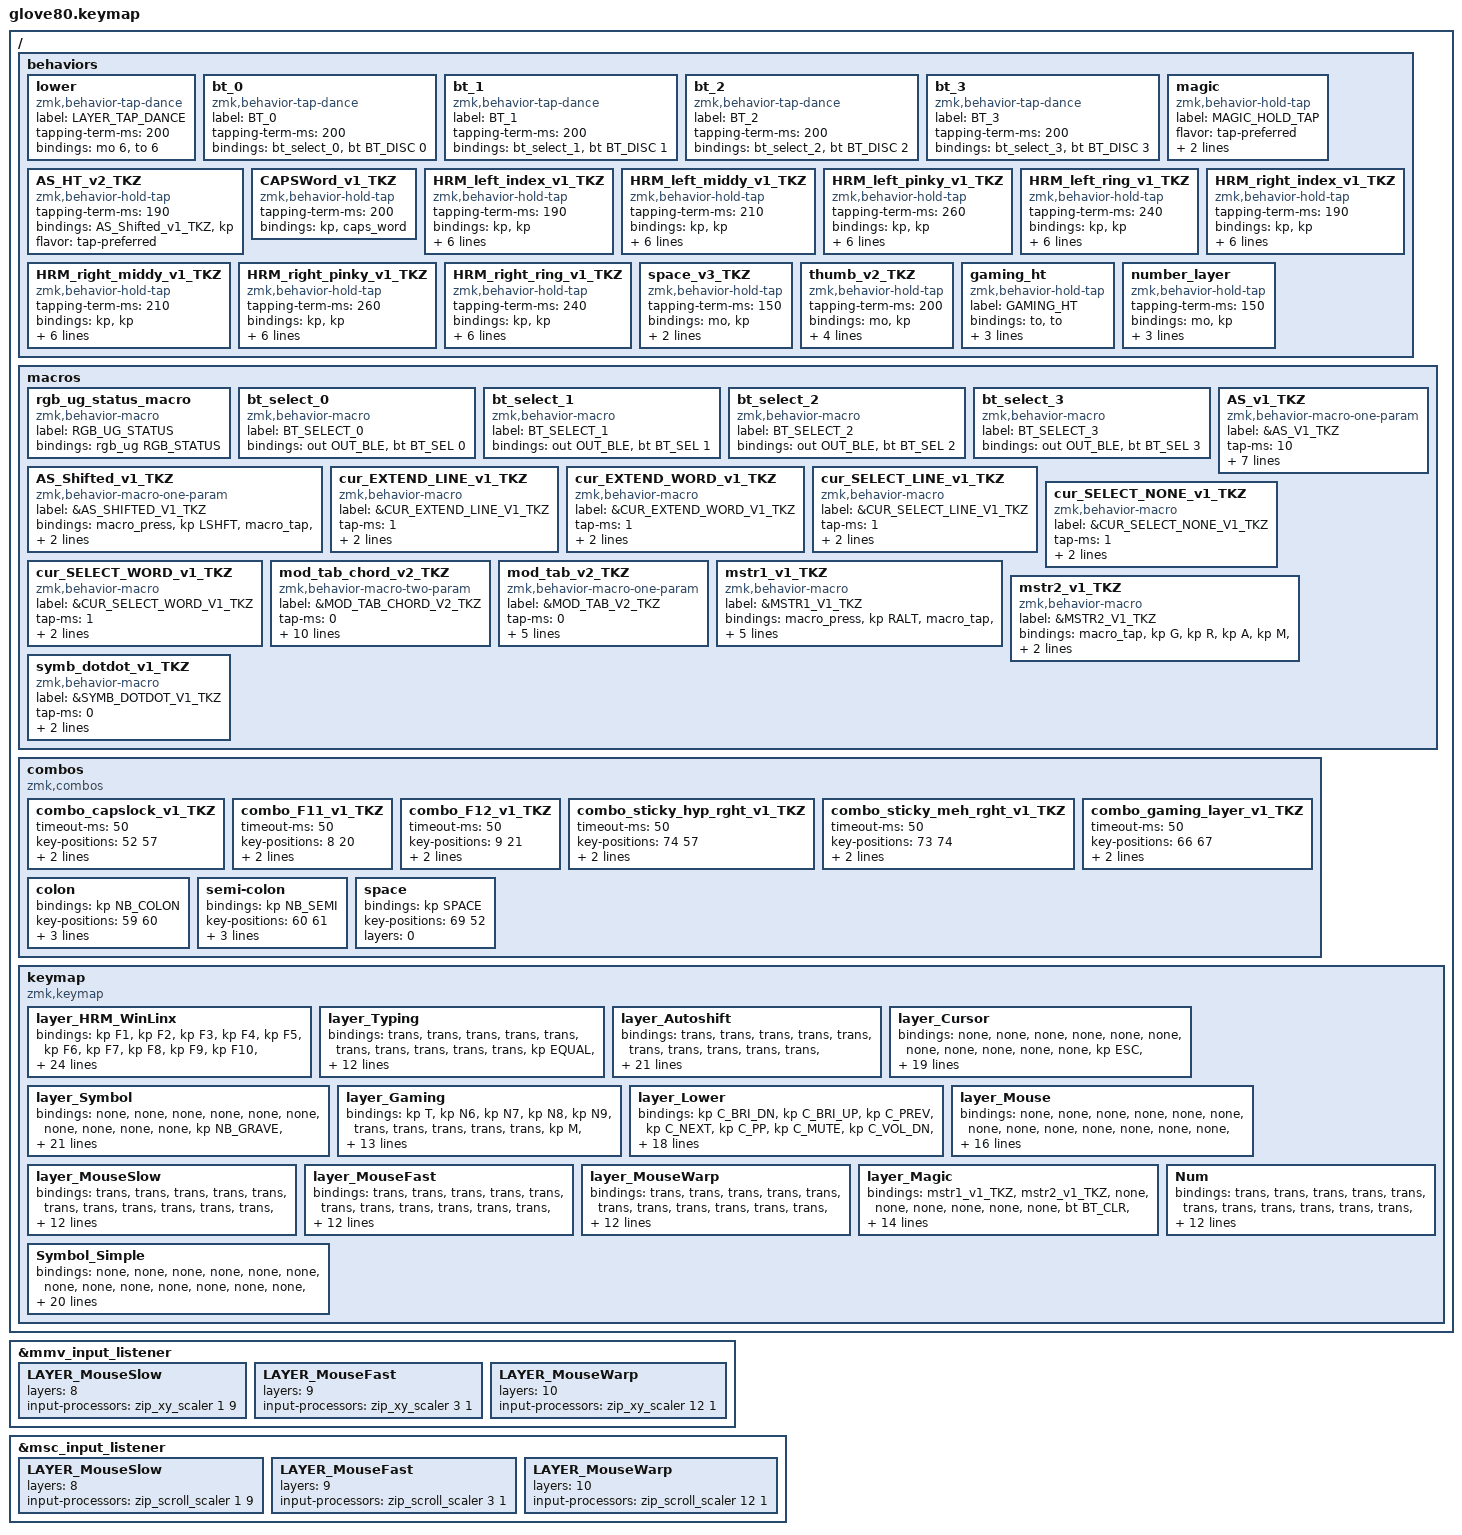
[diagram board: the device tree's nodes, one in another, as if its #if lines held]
/*
 * Copyright (c) 2020 The ZMK Contributors
 * Copyright (c) 2025 Innaworks Development Limited, trading as MoErgo
 *
 * SPDX-License-Identifier: MIT
 */
/* THIS FILE WAS GENERATED BY GLOVE80 LAYOUT EDITOR
 *
 * This file was generated automatically. You may or may not want to
 * edit it directly.
 */
/* Include all behavior includes needed */
/* On demand includes */

#include "keys_nb.h"
#include <dt-bindings/zmk/input_transform.h>
#include <input/processors.dtsi>
#include <behaviors.dtsi>
#include <dt-bindings/zmk/bt.h>
#include <dt-bindings/zmk/keys.h>
#include <dt-bindings/zmk/outputs.h>
#include <dt-bindings/zmk/pointing.h>
#include <dt-bindings/zmk/rgb.h>

/* Automatically generated layer name #define */

#define LAYER_HRM_WinLinx 0
#define LAYER_Typing 1
#define LAYER_Autoshift 2
#define LAYER_Cursor 3
#define LAYER_Symbol 4
#define LAYER_Gaming 5
#define LAYER_Lower 6
#define LAYER_Mouse 7
#define LAYER_MouseSlow 8
#define LAYER_MouseFast 9
#define LAYER_MouseWarp 10
#define LAYER_Magic 11
#define LAYER_Symbol_2 12

/* To deal with the situation where there is no Lower layer, to keep &lower happy */

#ifndef LAYER_Lower

#define LAYER_Lower 0

#endif

/* Custom Device-tree */
/* Input Listeners */

&mmv_input_listener {
    // LAYER_MouseSlow

    LAYER_MouseSlow {
        layers = <8>;
        input-processors = <&zip_xy_scaler 1 9>;
    };

    // LAYER_MouseFast

    LAYER_MouseFast {
        layers = <9>;
        input-processors = <&zip_xy_scaler 3 1>;
    };

    // LAYER_MouseFast

    LAYER_MouseWarp {
        layers = <10>;
        input-processors = <&zip_xy_scaler 12 1>;
    };
};

&msc_input_listener {
    // LAYER_MouseSlow

    LAYER_MouseSlow {
        layers = <8>;
        input-processors = <&zip_scroll_scaler 1 9>;
    };

    // LAYER_MouseFast

    LAYER_MouseFast {
        layers = <9>;
        input-processors = <&zip_scroll_scaler 3 1>;
    };

    // LAYER_MouseWarp

    LAYER_MouseWarp {
        layers = <10>;
        input-processors = <&zip_scroll_scaler 12 1>;
    };
};

/* System behavior and Macros */

/ {
    behaviors {
        // For the "layer" key, it'd nice to be able to use it as either a shift or a toggle.
        // Configure it as a tap dance, so the first tap (or hold) is a &mo and the second tap is a &to

        lower: lower {
            compatible = "zmk,behavior-tap-dance";
            label = "LAYER_TAP_DANCE";
            #binding-cells = <0>;
            tapping-term-ms = <200>;
            bindings = <&mo 6>, <&to 6>;
        };
    };
};

/ {
    macros {
        rgb_ug_status_macro: rgb_ug_status_macro {
            label = "RGB_UG_STATUS";
            compatible = "zmk,behavior-macro";
            #binding-cells = <0>;
            bindings = <&rgb_ug RGB_STATUS>;
        };
    };
};

/ {
    #ifdef BT_DISC_CMD

    behaviors {
        bt_0: bt_0 {
            compatible = "zmk,behavior-tap-dance";
            label = "BT_0";
            #binding-cells = <0>;
            tapping-term-ms = <200>;
            bindings = <&bt_select_0>, <&bt BT_DISC 0>;
        };

        bt_1: bt_1 {
            compatible = "zmk,behavior-tap-dance";
            label = "BT_1";
            #binding-cells = <0>;
            tapping-term-ms = <200>;
            bindings = <&bt_select_1>, <&bt BT_DISC 1>;
        };

        bt_2: bt_2 {
            compatible = "zmk,behavior-tap-dance";
            label = "BT_2";
            #binding-cells = <0>;
            tapping-term-ms = <200>;
            bindings = <&bt_select_2>, <&bt BT_DISC 2>;
        };

        bt_3: bt_3 {
            compatible = "zmk,behavior-tap-dance";
            label = "BT_3";
            #binding-cells = <0>;
            tapping-term-ms = <200>;
            bindings = <&bt_select_3>, <&bt BT_DISC 3>;
        };
    };

    macros {
        bt_select_0: bt_select_0 {
            label = "BT_SELECT_0";
            compatible = "zmk,behavior-macro";
            #binding-cells = <0>;
            bindings = <&out OUT_BLE &bt BT_SEL 0>;
        };

        bt_select_1: bt_select_1 {
            label = "BT_SELECT_1";
            compatible = "zmk,behavior-macro";
            #binding-cells = <0>;
            bindings = <&out OUT_BLE &bt BT_SEL 1>;
        };

        bt_select_2: bt_select_2 {
            label = "BT_SELECT_2";
            compatible = "zmk,behavior-macro";
            #binding-cells = <0>;
            bindings = <&out OUT_BLE &bt BT_SEL 2>;
        };

        bt_select_3: bt_select_3 {
            label = "BT_SELECT_3";
            compatible = "zmk,behavior-macro";
            #binding-cells = <0>;
            bindings = <&out OUT_BLE &bt BT_SEL 3>;
        };
    };

    #else

    macros {
        bt_0: bt_0 {
            label = "BT_0";
            compatible = "zmk,behavior-macro";
            #binding-cells = <0>;
            bindings = <&out OUT_BLE &bt BT_SEL 0>;
        };

        bt_1: bt_1 {
            label = "BT_1";
            compatible = "zmk,behavior-macro";
            #binding-cells = <0>;
            bindings = <&out OUT_BLE &bt BT_SEL 1>;
        };

        bt_2: bt_2 {
            label = "BT_2";
            compatible = "zmk,behavior-macro";
            #binding-cells = <0>;
            bindings = <&out OUT_BLE &bt BT_SEL 2>;
        };

        bt_3: bt_3 {
            label = "BT_3";
            compatible = "zmk,behavior-macro";
            #binding-cells = <0>;
            bindings = <&out OUT_BLE &bt BT_SEL 3>;
        };
    };

    #endif
};

/ {
    behaviors {
        magic: magic {
            compatible = "zmk,behavior-hold-tap";
            label = "MAGIC_HOLD_TAP";
            #binding-cells = <2>;
            flavor = "tap-preferred";
            tapping-term-ms = <200>;
            bindings = <&mo>, <&rgb_ug_status_macro>;
        };
    };
};

/* #define for key positions */

#define POS_LH_T1 52
#define POS_LH_T2 53
#define POS_LH_T3 54
#define POS_LH_T4 69
#define POS_LH_T5 70
#define POS_LH_T6 71
#define POS_LH_C1R2 15
#define POS_LH_C1R3 27
#define POS_LH_C1R4 39
#define POS_LH_C1R5 51
#define POS_LH_C2R1 4
#define POS_LH_C2R2 14
#define POS_LH_C2R3 26
#define POS_LH_C2R4 38
#define POS_LH_C2R5 50
#define POS_LH_C2R6 68
#define POS_LH_C3R1 3
#define POS_LH_C3R2 13
#define POS_LH_C3R3 25
#define POS_LH_C3R4 37
#define POS_LH_C3R5 49
#define POS_LH_C3R6 67
#define POS_LH_C4R1 2
#define POS_LH_C4R2 12
#define POS_LH_C4R3 24
#define POS_LH_C4R4 36
#define POS_LH_C4R5 48
#define POS_LH_C4R6 66
#define POS_LH_C5R1 1
#define POS_LH_C5R2 11
#define POS_LH_C5R3 23
#define POS_LH_C5R4 35
#define POS_LH_C5R5 47
#define POS_LH_C5R6 65
#define POS_LH_C6R1 0
#define POS_LH_C6R2 10
#define POS_LH_C6R3 22
#define POS_LH_C6R4 34
#define POS_LH_C6R5 46
#define POS_LH_C6R6 64
#define POS_RH_T1 57
#define POS_RH_T2 56
#define POS_RH_T3 55
#define POS_RH_T4 74
#define POS_RH_T5 73
#define POS_RH_T6 72
#define POS_RH_C1R2 16
#define POS_RH_C1R3 28
#define POS_RH_C1R4 40
#define POS_RH_C1R5 58
#define POS_RH_C2R1 5
#define POS_RH_C2R2 17
#define POS_RH_C2R3 29
#define POS_RH_C2R4 41
#define POS_RH_C2R5 59
#define POS_RH_C2R6 75
#define POS_RH_C3R1 6
#define POS_RH_C3R2 18
#define POS_RH_C3R3 30
#define POS_RH_C3R4 42
#define POS_RH_C3R5 60
#define POS_RH_C3R6 76
#define POS_RH_C4R1 7
#define POS_RH_C4R2 19
#define POS_RH_C4R3 31
#define POS_RH_C4R4 43
#define POS_RH_C4R5 61
#define POS_RH_C4R6 77
#define POS_RH_C5R1 8
#define POS_RH_C5R2 20
#define POS_RH_C5R3 32
#define POS_RH_C5R4 44
#define POS_RH_C5R5 62
#define POS_RH_C5R6 78
#define POS_RH_C6R1 9
#define POS_RH_C6R2 21
#define POS_RH_C6R3 33
#define POS_RH_C6R4 45
#define POS_RH_C6R5 63
#define POS_RH_C6R6 79

/* Custom Defined Behaviors */

/ {
};

/* Automatically generated macro definitions */

/ {
    macros {
        // AutoShift Helper- &AS main macro is chained to &AS_HT hold tap and &AS_Shifted macro - TailorKey

        AS_Shifted_v1_TKZ: AS_Shifted_v1_TKZ {
            label = "&AS_SHIFTED_V1_TKZ";
            compatible = "zmk,behavior-macro-one-param";
            #binding-cells = <1>;
            bindings =
                <&macro_press>,
                <&kp LSHFT>,
                <&macro_tap>,
                <&macro_param_1to1 &kp MACRO_PLACEHOLDER>,
                <&macro_release>,
                <&kp LSHFT>;
        };

        // AutoShift (Assign &AS to a Key) - &AS main macro is chained to &AS_HT hold tap and &AS_Shifted macro - TailorKey

        AS_v1_TKZ: AS_v1_TKZ {
            label = "&AS_V1_TKZ";
            compatible = "zmk,behavior-macro-one-param";
            #binding-cells = <1>;
            tap-ms = <10>;
            wait-ms = <10>;
            bindings =
                <&macro_press>,
                <&macro_param_1to1 &macro_param_1to2 &AS_HT_v2_TKZ MACRO_PLACEHOLDER MACRO_PLACEHOLDER>,
                <&macro_pause_for_release>,
                <&macro_release>,
                <&macro_param_1to1 &macro_param_1to2 &AS_HT_v2_TKZ MACRO_PLACEHOLDER MACRO_PLACEHOLDER>;
        };

        // Cursor Layer - Extent Line (seq) - TailorKey

        cur_EXTEND_LINE_v1_TKZ: cur_EXTEND_LINE_v1_TKZ {
            label = "&CUR_EXTEND_LINE_V1_TKZ";
            compatible = "zmk,behavior-macro";
            #binding-cells = <0>;
            tap-ms = <1>;
            wait-ms = <1>;
            bindings = <&kp LS(END)>;
        };

        // Cursor Layer - Extend Word (seq) - TailorKey

        cur_EXTEND_WORD_v1_TKZ: cur_EXTEND_WORD_v1_TKZ {
            label = "&CUR_EXTEND_WORD_V1_TKZ";
            compatible = "zmk,behavior-macro";
            #binding-cells = <0>;
            tap-ms = <1>;
            wait-ms = <1>;
            bindings = <&kp LC(LS(RIGHT))>;
        };

        // Cursor Layer - Select Line (seq) - TailorKey

        cur_SELECT_LINE_v1_TKZ: cur_SELECT_LINE_v1_TKZ {
            label = "&CUR_SELECT_LINE_V1_TKZ";
            compatible = "zmk,behavior-macro";
            #binding-cells = <0>;
            tap-ms = <1>;
            wait-ms = <1>;
            bindings = <&kp HOME &kp LS(END)>;
        };

        // Cursor Layer - Select None (seq) - TailorKey

        cur_SELECT_NONE_v1_TKZ: cur_SELECT_NONE_v1_TKZ {
            label = "&CUR_SELECT_NONE_V1_TKZ";
            compatible = "zmk,behavior-macro";
            #binding-cells = <0>;
            tap-ms = <1>;
            wait-ms = <1>;
            bindings = <&kp DOWN &kp UP &kp RIGHT &kp LEFT>;
        };

        // Cursor Layer - Select Word (seq) - TailorKey

        cur_SELECT_WORD_v1_TKZ: cur_SELECT_WORD_v1_TKZ {
            label = "&CUR_SELECT_WORD_V1_TKZ";
            compatible = "zmk,behavior-macro";
            #binding-cells = <0>;
            tap-ms = <1>;
            wait-ms = <1>;
            bindings = <&kp LC(LEFT) &kp LC(LS(RIGHT))>;
        };

        // mod_tab_switcher_chord -  TailorKey

        mod_tab_chord_v2_TKZ: mod_tab_chord_v2_TKZ {
            label = "&MOD_TAB_CHORD_V2_TKZ";
            compatible = "zmk,behavior-macro-two-param";
            #binding-cells = <2>;
            tap-ms = <0>;
            wait-ms = <0>;
            bindings =
                <&macro_press>,
                <&macro_param_2to1 &mo MACRO_PLACEHOLDER>,
                <&macro_press>,
                <&macro_param_1to1 &mod_tab_v2_TKZ MACRO_PLACEHOLDER>,
                <&macro_pause_for_release>,
                <&macro_release>,
                <&macro_param_1to1 &mod_tab_v2_TKZ MACRO_PLACEHOLDER>,
                <&macro_release>,
                <&macro_param_2to1 &mo MACRO_PLACEHOLDER>;
        };

        // mod_tab_switcher - TailorKey
        //
        //

        mod_tab_v2_TKZ: mod_tab_v2_TKZ {
            label = "&MOD_TAB_V2_TKZ";
            compatible = "zmk,behavior-macro-one-param";
            #binding-cells = <1>;
            tap-ms = <0>;
            wait-ms = <0>;
            bindings =
                <&macro_press>,
                <&macro_param_1to1 &kp MACRO_PLACEHOLDER>,
                <&macro_tap>,
                <&kp TAB>,
                <&macro_pause_for_release>,
                <&macro_release>,
                <&macro_param_1to1 &kp MACRO_PLACEHOLDER>;
        };

        // macro string1 sample - Magic Layer F1 - Text output sample macro 1 "¡Hola!" - TailorKey

        mstr1_v1_TKZ: mstr1_v1_TKZ {
            label = "&MSTR1_V1_TKZ";
            compatible = "zmk,behavior-macro";
            #binding-cells = <0>;
            bindings =
                <&macro_press>,
                <&kp RALT>,
                <&macro_tap>,
                <&kp KP_N0 &kp KP_N1 &kp KP_N6 &kp KP_N1>,
                <&macro_release>,
                <&kp RALT>,
                <&macro_press>,
                <&kp LSHFT>,
                <&macro_tap>,
                <&kp H>,
                <&macro_release>,
                <&kp LSHFT>,
                <&macro_tap>,
                <&kp O &kp L &kp A &kp EXCL &kp SPACE &kp RET>;
        };

        // macro string2 sample - Magic Layer F2 - Text output sample macro 2 "grammar check: <paste>" - TailorKey

        mstr2_v1_TKZ: mstr2_v1_TKZ {
            label = "&MSTR2_V1_TKZ";
            compatible = "zmk,behavior-macro";
            #binding-cells = <0>;
            bindings =
                <&macro_tap>,
                <&kp G &kp R &kp A &kp M &kp M &kp A &kp R &kp SPACE &kp C &kp H &kp E &kp C &kp K &kp COLON &kp LC(V) &kp RET>;
        };

        // Symbol layer dot dot

        symb_dotdot_v1_TKZ: symb_dotdot_v1_TKZ {
            label = "&SYMB_DOTDOT_V1_TKZ";
            compatible = "zmk,behavior-macro";
            #binding-cells = <0>;
            tap-ms = <0>;
            wait-ms = <0>;
            bindings = <&macro_tap>, <&kp DOT &kp DOT>;
        };
    };
};

/* Automatically generated behavior definitions */

/ {
    behaviors {
        // AutoShift Helper - &AS main macro is chained to &AS_HT hold tap and &AS_Shifted macro. For faster typists, it is recommended to decrease the tapping-term-ms value. A suggested value is 135 ms.
        // More: https://github.com/nickcoutsos/keymap-editor/wiki/Autoshift-using-ZMK-behaviors

        AS_HT_v2_TKZ: AS_HT_v2_TKZ {
            compatible = "zmk,behavior-hold-tap";
            #binding-cells = <2>;
            tapping-term-ms = <190>;
            bindings = <&AS_Shifted_v1_TKZ>, <&kp>;

            flavor = "tap-preferred";
        };

        // Capsword helper - tap for caps_word - hold for key press

        CAPSWord_v1_TKZ: CAPSWord_v1_TKZ {
            compatible = "zmk,behavior-hold-tap";
            #binding-cells = <2>;
            tapping-term-ms = <200>;
            bindings = <&kp>, <&caps_word>;
        };

        // Homerow Mod for the left index finger - TailorKey.
        // For advanced tuning of HRM values, see: https://docs.google.com/spreadsheets/d/1ESgObQelyz4lnKlfwLYsmofLJulOMK5RdGBsopLe2o8

        HRM_left_index_v1_TKZ: HRM_left_index_v1_TKZ {
            compatible = "zmk,behavior-hold-tap";
            #binding-cells = <2>;
            tapping-term-ms = <190>;
            bindings = <&kp>, <&kp>;

            flavor = "tap-preferred";
            quick-tap-ms = <300>;
            require-prior-idle-ms = <100>;
            hold-trigger-key-positions = <57 56 55 72 73 74 5 6 7 8 16 17 18 19 20 28 29 30 31 32 40 41 42 43 44 58 59 60 61 62 75 76 77 78 9 21 33 45 63 79 52 53 54 70 71 69>;
            hold-trigger-on-release;
        };

        // Homerow Mod for the left middle finger - TailorKey

        HRM_left_middy_v1_TKZ: HRM_left_middy_v1_TKZ {
            compatible = "zmk,behavior-hold-tap";
            #binding-cells = <2>;
            tapping-term-ms = <210>;
            bindings = <&kp>, <&kp>;

            flavor = "tap-preferred";
            quick-tap-ms = <300>;
            require-prior-idle-ms = <150>;
            hold-trigger-key-positions = <57 56 55 72 73 74 5 6 7 8 16 17 18 19 20 28 29 30 31 32 40 41 42 43 44 58 59 60 61 62 75 76 77 78 9 21 33 45 63 79 52 53 54 69 70 71>;
            hold-trigger-on-release;
        };

        // Homerow Mod for the left pinky - TailorKey

        HRM_left_pinky_v1_TKZ: HRM_left_pinky_v1_TKZ {
            compatible = "zmk,behavior-hold-tap";
            #binding-cells = <2>;
            tapping-term-ms = <260>;
            bindings = <&kp>, <&kp>;

            flavor = "tap-preferred";
            quick-tap-ms = <300>;
            require-prior-idle-ms = <150>;
            hold-trigger-key-positions = <57 56 55 72 73 74 5 6 7 8 9 16 17 18 19 20 21 29 30 31 32 33 42 43 44 45 60 61 62 63 28 40 41 58 59 75 76 77 79 78 52 53 54 69 70 71>;
            hold-trigger-on-release;
        };

        // Homerow Mod for the left ring finger 1 - TailorKey

        HRM_left_ring_v1_TKZ: HRM_left_ring_v1_TKZ {
            compatible = "zmk,behavior-hold-tap";
            #binding-cells = <2>;
            tapping-term-ms = <240>;
            bindings = <&kp>, <&kp>;

            flavor = "tap-preferred";
            quick-tap-ms = <300>;
            require-prior-idle-ms = <150>;
            hold-trigger-key-positions = <57 56 55 72 73 74 5 6 7 8 16 17 18 19 20 28 29 30 31 32 40 41 42 43 44 58 59 60 61 62 75 76 77 78 9 21 33 45 63 79 52 53 54 69 70 71>;
            hold-trigger-on-release;
        };

        // Homerow Mod for the right index finger - TailorKey

        HRM_right_index_v1_TKZ: HRM_right_index_v1_TKZ {
            compatible = "zmk,behavior-hold-tap";
            #binding-cells = <2>;
            tapping-term-ms = <190>;
            bindings = <&kp>, <&kp>;

            flavor = "tap-preferred";
            quick-tap-ms = <300>;
            require-prior-idle-ms = <100>;
            hold-trigger-key-positions = <52 53 54 71 70 69 0 1 10 11 12 13 14 22 23 24 25 26 27 34 35 36 37 38 39 46 47 48 49 50 51 64 65 66 67 68 15 4 2 3 55 56 57 72 73 74>;
            hold-trigger-on-release;
        };

        // Homerow Mod for the right middle finger - TailorKey

        HRM_right_middy_v1_TKZ: HRM_right_middy_v1_TKZ {
            compatible = "zmk,behavior-hold-tap";
            #binding-cells = <2>;
            tapping-term-ms = <210>;
            bindings = <&kp>, <&kp>;

            flavor = "tap-preferred";
            quick-tap-ms = <300>;
            require-prior-idle-ms = <150>;
            hold-trigger-key-positions = <52 53 54 71 70 69 0 1 10 11 12 13 14 22 23 24 25 26 27 34 35 36 37 38 39 46 47 48 49 50 51 64 65 66 67 68 15 4 2 3 55 56 57 72 73 74>;
            hold-trigger-on-release;
        };

        // Homerow Mod for the right pinky - TailorKey

        HRM_right_pinky_v1_TKZ: HRM_right_pinky_v1_TKZ {
            compatible = "zmk,behavior-hold-tap";
            #binding-cells = <2>;
            tapping-term-ms = <260>;
            bindings = <&kp>, <&kp>;

            flavor = "tap-preferred";
            quick-tap-ms = <300>;
            require-prior-idle-ms = <150>;
            hold-trigger-key-positions = <52 53 54 71 70 69 0 1 10 11 12 13 14 22 23 24 25 26 27 34 35 36 37 38 39 46 47 48 49 50 51 64 65 66 67 68 15 4 2 3 55 56 57 72 73 74>;
            hold-trigger-on-release;
        };

        // Homerow Mod for the right ring 1 - TailorKey
        //

        HRM_right_ring_v1_TKZ: HRM_right_ring_v1_TKZ {
            compatible = "zmk,behavior-hold-tap";
            #binding-cells = <2>;
            tapping-term-ms = <240>;
            bindings = <&kp>, <&kp>;

            flavor = "tap-preferred";
            quick-tap-ms = <300>;
            require-prior-idle-ms = <150>;
            hold-trigger-key-positions = <52 53 54 71 70 69 0 1 10 11 12 13 14 22 23 24 25 26 27 34 35 36 37 38 39 46 47 48 49 50 51 64 65 66 67 68 15 4 2 3 55 56 57 72 73 74>;
            hold-trigger-on-release;
        };

        // space_layer_access - TailorKey

        space_v3_TKZ: space_v3_TKZ {
            compatible = "zmk,behavior-hold-tap";
            #binding-cells = <2>;
            tapping-term-ms = <150>;
            bindings = <&mo>, <&kp>;

            flavor = "balanced";
            quick-tap-ms = <200>;
        };

        // thumb_layer_access - TailorKey

        thumb_v2_TKZ: thumb_v2_TKZ {
            compatible = "zmk,behavior-hold-tap";
            #binding-cells = <2>;
            tapping-term-ms = <200>;
            bindings = <&mo>, <&kp>;

            flavor = "balanced";
            quick-tap-ms = <300>;
            hold-trigger-key-positions = <5 6 7 8 9 16 17 18 19 20 21 28 29 30 31 32 33 40 41 42 43 44 45 55 56 57 58 59 60 61 62 63 72 73 74 75 76 77 78 79>;
        };

        gaming_ht: gaming_ht {
            compatible = "zmk,behavior-hold-tap";
            label = "GAMING_HT";
            bindings = <&to>, <&to>;

            #binding-cells = <2>;
            tapping-term-ms = <150>;
            quick-tap-ms = <200>;
            flavor = "balanced";
        };

        number_layer: number_layer {
            compatible = "zmk,behavior-hold-tap";
            #binding-cells = <2>;
            tapping-term-ms = <150>;
            bindings = <&mo>, <&kp>;

            flavor = "balanced";
            quick-tap-ms = <200>;
            label = "NUMBER_LAYER";
        };
    };
};

/* Automatically generated combos definitions */

/ {
    combos {
        compatible = "zmk,combos";

        // capslock when pressing both T1's - TailorKey

        combo_capslock_v1_TKZ {
            timeout-ms = <50>;
            key-positions = <52 57>;
            bindings = <&kp CAPS>;
            layers = <0 2>;
        };

        // F11 on RH_C5 and RH_R1+R2 - TailorKey

        combo_F11_v1_TKZ {
            timeout-ms = <50>;
            key-positions = <8 20>;
            bindings = <&kp F11>;
            layers = <0 2>;
        };

        // F12 on RH_C6 and RH_R1+R2 - TailorKey

        combo_F12_v1_TKZ {
            timeout-ms = <50>;
            key-positions = <9 21>;
            bindings = <&kp F12>;
            layers = <0 2>;
        };

        // sticky "hyper" modifiers (Win + Alt + Ctrl + Shift) - Use with Tab - TailorKey

        combo_sticky_hyp_rght_v1_TKZ {
            timeout-ms = <50>;
            key-positions = <74 57>;
            bindings = <&sk LG(LA(LC(LSHFT)))>;
            layers = <0 2>;
        };

        // sticky "meh" modifiers (Alt + Ctrl + Shift) - Use with Tab - TailorKey

        combo_sticky_meh_rght_v1_TKZ {
            timeout-ms = <50>;
            key-positions = <73 74>;
            bindings = <&sk LA(LC(LSHFT))>;
            layers = <0 2>;
        };

        // toggle gaming layer - TailorKey

        combo_gaming_layer_v1_TKZ {
            timeout-ms = <50>;
            key-positions = <66 67>;
            bindings = <&gaming_ht 5 0>;
            layers = <0 5>;
        };

        colon {
            bindings = <&kp NB_COLON>;
            key-positions = <59 60>;
            layers = <0>;
            timeout-ms = <20>;
            require-prior-idle-ms = <110>;
        };

        semi-colon {
            bindings = <&kp NB_SEMI>;
            key-positions = <60 61>;
            timeout-ms = <20>;
            require-prior-idle-ms = <110>;
            layers = <0>;
        };

        space {
            bindings = <&kp SPACE>;
            key-positions = <69 52>;
            layers = <0>;
        };
    };
};

/* Automatically generated keymap */

/ {
    keymap {
        compatible = "zmk,keymap";

        layer_HRM_WinLinx {
            bindings = <
&kp F1          &kp F2                         &kp F3                        &kp F4                          &kp F5                                                                                                                                                                &kp F6                                &kp F7                                  &kp F8                             &kp F9                              &kp F10
&kp NB_EQUAL    &kp N1                         &kp N2                        &kp N3                          &kp N4                          &kp N5                                                                                                                        &kp N6  &kp N7                                &kp N8                                  &kp N9                             &kp N0                              &none
&kp TAB         &kp Q                          &kp W                         &kp F                           &kp P                           &kp B                                                                                                                         &kp J   &kp L                                 &kp U                                   &kp Y                              &kp NB_SEMICOLON                    &kp NB_BSLH
&kp ESC         &HRM_left_pinky_v1_TKZ LGUI A  &HRM_left_ring_v1_TKZ LALT R  &HRM_left_middy_v1_TKZ LCTRL S  &HRM_left_index_v1_TKZ LSHFT T  &kp G                                                                                                                         &kp M   &HRM_right_index_v1_TKZ LEFT_SHIFT N  &HRM_right_middy_v1_TKZ LEFT_CONTROL E  &HRM_right_ring_v1_TKZ LEFT_ALT I  &HRM_right_pinky_v1_TKZ LEFT_GUI O  &kp NB_APOSTROPHE
&kp LEFT_SHIFT  &kp Z                          &kp X                         &kp C                           &kp D                           &kp V   &gaming_ht 5 0         &gaming_ht 5 0        &kp LEFT_CONTROL  &kp LGUI  &lower               &number_layer 13 SPACE  &kp K   &kp H                                 &kp NB_COMMA                            &kp NB_DOT                         &kp NB_FSLH                         &kp PG_UP
&magic 11 0     &kp DELETE                     &kp INSERT                    &kp HOME                        &kp ENTER                               &thumb_v2_TKZ 3 SPACE  &number_layer 13 TAB  &gaming_ht 5 0    &kp RALT  &thumb_v2_TKZ 3 RET  &space_v3_TKZ 12 BSPC           &kp NB_COLON                          &kp NB_SEMICOLON                        &kp NB_AE                          &kp NB_O_SLASH                      &kp NB_A_RING
            >;
        };

        layer_Typing {
            bindings = <
&trans       &trans  &trans  &trans  &trans                                                                  &trans  &trans     &trans    &trans    &trans
&kp EQUAL    &kp N1  &kp N2  &kp N3  &kp N4  &kp N5                                                  &kp N6  &kp N7  &kp N8     &kp N9    &kp N0    &kp MINUS
&trans       &kp Q   &kp W   &kp E   &kp R   &kp T                                                   &kp Y   &kp U   &kp I      &kp O     &kp P     &kp BSLH
&trans       &kp A   &kp S   &kp D   &kp F   &kp G                                                   &kp H   &kp J   &kp K      &kp L     &kp SEMI  &kp APOS
&kp GRAVE    &kp Z   &kp X   &kp C   &kp V   &kp B   &trans  &trans  &trans  &trans  &trans  &trans  &kp N   &kp M   &kp COMMA  &kp DOT   &kp FSLH  &trans
&magic 11 0  &trans  &trans  &trans  &trans          &trans  &trans  &trans  &trans  &trans  &trans          &trans  &trans     &kp LBKT  &kp RBKT  &trans
            >;
        };

        layer_Autoshift {
            bindings = <
&trans            &trans         &trans         &trans         &trans                                                                                       &trans         &trans            &trans           &trans           &trans
&AS_v1_TKZ EQUAL  &AS_v1_TKZ N1  &AS_v1_TKZ N2  &AS_v1_TKZ N3  &AS_v1_TKZ N4  &AS_v1_TKZ N5                                                  &AS_v1_TKZ N6  &AS_v1_TKZ N7  &AS_v1_TKZ N8     &AS_v1_TKZ N9    &AS_v1_TKZ N0    &AS_v1_TKZ MINUS
&trans            &AS_v1_TKZ Q   &AS_v1_TKZ W   &AS_v1_TKZ F   &AS_v1_TKZ P   &AS_v1_TKZ B                                                   &AS_v1_TKZ J   &AS_v1_TKZ L   &AS_v1_TKZ U      &AS_v1_TKZ Y     &AS_v1_TKZ SEMI  &AS_v1_TKZ BSLH
&trans            &AS_v1_TKZ A   &AS_v1_TKZ R   &AS_v1_TKZ S   &AS_v1_TKZ T   &AS_v1_TKZ G                                                   &AS_v1_TKZ M   &AS_v1_TKZ N   &AS_v1_TKZ E      &AS_v1_TKZ I     &AS_v1_TKZ O     &AS_v1_TKZ SQT
&AS_v1_TKZ GRAVE  &AS_v1_TKZ Z   &AS_v1_TKZ X   &AS_v1_TKZ C   &AS_v1_TKZ D   &AS_v1_TKZ V   &trans  &trans  &trans  &trans  &trans  &trans  &AS_v1_TKZ K   &AS_v1_TKZ H   &AS_v1_TKZ COMMA  &AS_v1_TKZ DOT   &AS_v1_TKZ FSLH  &trans
&magic 11 0       &trans         &trans         &trans         &trans                        &trans  &trans  &trans  &trans  &trans  &trans                 &trans         &trans            &AS_v1_TKZ LBKT  &AS_v1_TKZ RBKT  &trans
            >;
        };

        layer_Cursor {
            bindings = <
&none      &none      &none                    &none                    &none                                                                                                                                                               &none        &none          &none        &none      &none
&none      &kp ESC    &kp INS                  &kp LS(TAB)              &kp DEL    &none                                                                                                                                         &none      &none        &none          &none        &none      &none
&none      &kp RET    &kp SPACE                &kp TAB                  &kp BSPC   &kp LC(X)                                                                                                                                     &kp LC(X)  &kp LS(TAB)  &kp LC(Z)      &kp LC(Y)    &kp TAB    &none
&sk LSHFT  &kp LGUI   &kp LALT                 &kp LCTRL                &kp LSHFT  &kp LC(C)                                                                                                                                     &kp LC(C)  &kp LEFT     &kp DOWN       &kp UP       &kp RIGHT  &sk RSHFT
&kp LC(L)  &kp LC(A)  &cur_SELECT_LINE_v1_TKZ  &cur_SELECT_WORD_v1_TKZ  &kp LC(F)  &kp LC(V)  &mod_tab_v2_TKZ LALT  &mod_tab_v2_TKZ LGUI   &kp PSCRN  &cur_SELECT_NONE_v1_TKZ  &cur_EXTEND_LINE_v1_TKZ  &cur_EXTEND_WORD_v1_TKZ  &kp LC(V)  &kp HOME     &kp PAGE_DOWN  &kp PAGE_UP  &kp END    &kp LC(L)
&kp LC(K)  &kp LC(Z)  &kp LC(Y)                &kp LC(LS(G))            &kp LC(G)             &none                 &mod_tab_v2_TKZ LCTRL  &kp LG(D)  &kp LC(A)                &cur_SELECT_LINE_v1_TKZ  &cur_SELECT_WORD_v1_TKZ             &kp LC(F)    &kp LC(LS(G))  &kp LC(G)    &kp LC(H)  &kp LC(K)
            >;
        };

        layer_Symbol {
            bindings = <
&none                &none                 &none                    &none                     &none                                                                                                                         &none      &none         &none      &none     &none
&kp NB_GRAVE         &kp NB_RIGHT_BRACKET  &kp NB_LEFT_PARENTHESIS  &kp NB_RIGHT_PARENTHESIS  &kp NB_COMMA         &kp NB_DOT                                                                         &none                 &none      &none         &none      &none     &none
&kp NB_LEFT_BRACKET  &kp NB_EXCL           &kp NB_LEFT_BRACE        &kp NB_RIGHT_BRACE        &kp NB_SEMICOLON     &kp NB_QUESTION                                                                    &kp NB_GRAVE          &sk RSHFT  &sk NB_CARET  &sk RALT   &sk RGUI  &none
&kp NB_HASH          &kp NB_CARET          &kp NB_EQUAL             &kp NB_UNDERSCORE         &kp NB_DOLLAR        &kp NB_ASTERISK                                                                    &kp NB_DOUBLE_QUOTES  &kp BSPC   &kp TAB       &kp SPACE  &kp RET   &none
&kp NB_TILDE         &kp NB_LESS_THAN      &kp NB_PIPE              &kp NB_MINUS              &kp NB_GREATER_THAN  &kp NB_SLASH     &kp NB_BACKSLASH  &kp NB_DOT    &kp NB_STAR  &none  &none  &none  &kp NB_APOSTROPHE     &kp DEL    &kp LS(TAB)   &kp INS    &kp ESC   &none
&symb_dotdot_v1_TKZ  &kp NB_AMPERSAND      &kp NB_APOSTROPHE        &kp NB_DOUBLE_QUOTES      &kp NB_PLUS                           &kp NB_PERCENT    &kp NB_COLON  &kp NB_AT    &none  &none  &none                        &none      &none         &none      &none     &none
            >;
        };

        layer_Gaming {
            bindings = <
&kp T       &kp N6        &kp N7  &kp N8        &kp N9                                                                                                    &trans  &trans  &trans  &trans  &trans
&kp M       &kp NUMBER_5  &kp N1  &kp NUMBER_2  &kp NUMBER_3  &kp NUMBER_4                                                                        &trans  &trans  &trans  &trans  &trans  &trans
&kp I       &kp TAB       &kp Q   &kp W         &kp E         &kp R                                                                               &trans  &trans  &trans  &trans  &trans  &trans
&kp ESCAPE  &kp LSHFT     &kp A   &kp S         &kp D         &kp F                                                                               &trans  &trans  &trans  &trans  &trans  &trans
&kp G       &kp LCTRL     &kp Z   &kp X         &kp C         &kp V         &gaming_ht 5 0  &kp LALT      &kp V           &trans  &trans  &trans  &trans  &trans  &trans  &trans  &trans  &trans
&kp B       &kp LCTRL     &kp Z   &kp L         &kp N                       &kp SPACE       &kp LEFT_ALT  &gaming_ht 5 0  &trans  &trans  &trans          &trans  &trans  &trans  &trans  &trans
            >;
        };

        layer_Lower {
            bindings = <
&kp C_BRI_DN  &kp C_BRI_UP  &kp C_PREV  &kp C_NEXT         &kp C_PP                                                                                           &kp C_MUTE  &kp C_VOL_DN  &kp C_VOL_UP  &none            &kp PAUSE_BREAK
&trans        &none         &none       &none              &none            &kp HOME                                                   &kp LEFT_PARENTHESIS   &kp KP_NUM  &kp EQUAL     &kp KP_SLASH  &kp KP_MULTIPLY  &kp PRINTSCREEN
&trans        &none         &kp C_MUTE  &kp C_VOLUME_DOWN  &kp C_VOLUME_UP  &kp END                                                    &kp RIGHT_PARENTHESIS  &kp KP_N7   &kp KP_N8     &kp KP_N9     &kp KP_MINUS     &kp SCROLLLOCK
&trans        &none         &none       &kp C_STOP         &kp C_PLAY       &kp PG_UP                                                  &kp PERCENT            &kp KP_N4   &kp KP_N5     &kp KP_N6     &kp KP_PLUS      &none
&trans        &kp K_APP     &none       &kp C_PREV         &kp C_NEXT       &kp PG_DN  &trans  &trans  &to 0   &trans  &trans  &trans  &kp COMMA              &kp KP_N1   &kp KP_N2     &kp KP_N3     &kp KP_ENTER     &trans
&magic 11 0   &kp CAPS      &kp INS     &kp F11            &kp F12                     &trans  &trans  &trans  &trans  &trans  &trans                         &kp KP_N0   &kp KP_N0     &kp KP_DOT    &kp KP_ENTER     &trans
            >;
        };

        layer_Mouse {
            bindings = <
&none  &none           &none           &none           &none                                                                                                                 &none           &none           &none            &none      &none
&none  &none           &none           &none           &none            &none                                                                                &none           &none           &none           &none            &none      &none
&none  &none           &msc SCRL_LEFT  &mmv MOVE_UP    &msc SCRL_RIGHT  &none                                                                                &none           &sk RSHFT       &sk RCTRL       &sk RALT         &sk RGUI   &none
&none  &msc SCRL_UP    &mmv MOVE_LEFT  &mmv MOVE_DOWN  &mmv MOVE_RIGHT  &msc SCRL_UP                                                                         &msc SCRL_UP    &mo 9           &mo 10          &mo 8            &mkp LCLK  &mkp MB4
&none  &msc SCRL_DOWN  &mo 8           &mo 10          &mo 9            &msc SCRL_DOWN  &mkp MCLK  &kp K_APP  &mkp MB5  &kp LC(X)  &kp LC(C)  &kp LC(LC(V))  &msc SCRL_DOWN  &msc SCRL_LEFT  &mmv MOVE_UP    &msc SCRL_RIGHT  &mkp RCLK  &mkp MB5
&none  &none           &none           &none           &none                            &mkp LCLK  &mkp RCLK  &mkp MB4  &none      &none      &none                          &mmv MOVE_LEFT  &mmv MOVE_DOWN  &mmv MOVE_RIGHT  &mkp MCLK  &kp K_APP
            >;
        };

        layer_MouseSlow {
            bindings = <
&trans  &trans  &trans  &trans  &trans                                                                  &trans  &trans  &trans  &trans  &trans
&trans  &trans  &trans  &trans  &trans  &trans                                                  &trans  &trans  &trans  &trans  &trans  &trans
&trans  &trans  &trans  &trans  &trans  &trans                                                  &trans  &trans  &trans  &trans  &trans  &trans
&trans  &trans  &trans  &trans  &trans  &trans                                                  &trans  &trans  &trans  &trans  &trans  &trans
&trans  &trans  &trans  &trans  &trans  &trans  &trans  &trans  &trans  &trans  &trans  &trans  &trans  &trans  &trans  &trans  &trans  &trans
&trans  &trans  &trans  &trans  &trans          &trans  &trans  &trans  &trans  &trans  &trans          &trans  &trans  &trans  &trans  &trans
            >;
        };

        layer_MouseFast {
            bindings = <
&trans  &trans  &trans  &trans  &trans                                                                  &trans  &trans  &trans  &trans  &trans
&trans  &trans  &trans  &trans  &trans  &trans                                                  &trans  &trans  &trans  &trans  &trans  &trans
&trans  &trans  &trans  &trans  &trans  &trans                                                  &trans  &trans  &trans  &trans  &trans  &trans
&trans  &trans  &trans  &trans  &trans  &trans                                                  &trans  &trans  &trans  &trans  &trans  &trans
&trans  &trans  &trans  &trans  &trans  &trans  &trans  &trans  &trans  &trans  &trans  &trans  &trans  &trans  &trans  &trans  &trans  &trans
&trans  &trans  &trans  &trans  &trans          &trans  &trans  &trans  &trans  &trans  &trans          &trans  &trans  &trans  &trans  &trans
            >;
        };

        layer_MouseWarp {
            bindings = <
&trans  &trans  &trans  &trans  &trans                                                                  &trans  &trans  &trans  &trans  &trans
&trans  &trans  &trans  &trans  &trans  &trans                                                  &trans  &trans  &trans  &trans  &trans  &trans
&trans  &trans  &trans  &trans  &trans  &trans                                                  &trans  &trans  &trans  &trans  &trans  &trans
&trans  &trans  &trans  &trans  &trans  &trans                                                  &trans  &trans  &trans  &trans  &trans  &trans
&trans  &trans  &trans  &trans  &trans  &trans  &trans  &trans  &trans  &trans  &trans  &trans  &trans  &trans  &trans  &trans  &trans  &trans
&trans  &trans  &trans  &trans  &trans          &trans  &trans  &trans  &trans  &trans  &trans          &trans  &trans  &trans  &trans  &trans
            >;
        };

        layer_Magic {
            bindings = <
&mstr1_v1_TKZ  &mstr2_v1_TKZ    &none            &none            &none                                                                                     &none  &none  &none  &bt BT_CLR  &bt BT_CLR_ALL
&to 0          &none            &to 1            &none            &none            &to 2                                                             &none  &none  &none  &none  &none       &none
&none          &rgb_ug RGB_SPI  &rgb_ug RGB_SAI  &rgb_ug RGB_HUI  &rgb_ug RGB_BRI  &rgb_ug RGB_TOG                                                   &none  &none  &none  &none  &none       &none
&bootloader    &rgb_ug RGB_SPD  &rgb_ug RGB_SAD  &rgb_ug RGB_HUD  &rgb_ug RGB_BRD  &rgb_ug RGB_EFF                                                   &none  &none  &none  &none  &none       &bootloader
&sys_reset     &none            &none            &none            &none            &none            &bt_2  &bt_3  &none         &none  &none  &none  &none  &none  &none  &none  &none       &sys_reset
&none          &none            &none            &none            &none                             &bt_0  &bt_1  &out OUT_USB  &none  &none  &none         &none  &none  &none  &none       &none
            >;
        };

        Symbol_Simple {
            bindings = <
&none                &none                    &none                &none                 &none                                                                                                                        &none      &none         &none      &none     &none
&none                &none                    &none                &kp NB_PIPE           &none                     &none                                                                        &none                 &none      &none         &none      &none     &none
&none                &kp NB_EXCL              &kp NB_LEFT_BRACE    &kp NB_RIGHT_BRACE    &kp NB_AMPERSAND          &kp NB_QUESTION                                                              &kp NB_GRAVE          &sk RSHFT  &sk NB_CARET  &sk RALT   &sk RGUI  &none
&kp NB_HASH          &kp NB_LEFT_PARENTHESIS  &kp NB_EQUAL         &kp NB_UNDERSCORE     &kp NB_RIGHT_PARENTHESIS  &kp NB_ASTERISK                                                              &kp NB_DOUBLE_QUOTES  &kp BSPC   &kp TAB       &kp SPACE  &kp RET   &none
&kp NB_TILDE         &kp NB_LESS_THAN         &kp NB_DOLLAR        &kp NB_MINUS          &kp NB_GREATER_THAN       &kp NB_CARET     &kp NB_BACKSLASH  &kp NB_DOT    &none  &none  &none  &none  &kp NB_APOSTROPHE     &kp DEL    &kp LS(TAB)   &kp INS    &kp ESC   &none
&symb_dotdot_v1_TKZ  &kp NB_AT                &kp NB_LEFT_BRACKET  &kp NB_RIGHT_BRACKET  &kp NB_PLUS                                &kp NB_PERCENT    &kp NB_SLASH  &none  &none  &none  &none                        &none      &none         &none      &none     &none
            >;
        };

        Num {
            bindings = <
&trans  &trans        &trans  &trans  &trans                                                                  &trans  &trans  &trans   &trans  &trans
&trans  &trans        &trans  &trans  &trans  &trans                                                  &trans  &trans  &trans  &trans   &trans  &trans
&trans  &trans        &trans  &kp N7  &kp N8  &kp N9                                                  &kp F7  &kp F8  &kp F9  &kp F10  &trans  &trans
&trans  &kp NB_COMMA  &trans  &kp N4  &kp N5  &kp N6                                                  &kp F4  &kp F5  &kp F6  &kp F11  &trans  &trans
&trans  &kp NB_DOT    &kp N0  &kp N1  &kp N2  &kp N3  &trans  &trans  &trans  &trans  &trans  &trans  &kp F1  &kp F2  &kp F3  &kp F12  &trans  &trans
&trans  &trans        &trans  &trans  &trans          &trans  &trans  &trans  &trans  &trans  &trans          &trans  &trans  &trans   &trans  &trans
            >;
        };
    };
};
